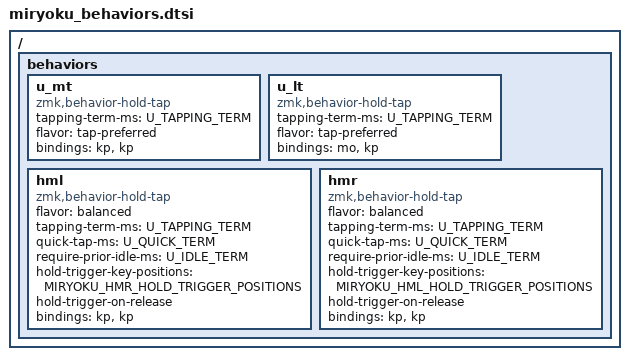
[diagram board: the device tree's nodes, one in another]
// Copyright 2022 Manna Harbour
// https://github.com/manna-harbour/miryoku
/ {
  behaviors {
    u_mt: u_mt {
      compatible = "zmk,behavior-hold-tap";
      #binding-cells = <2>;
      tapping-term-ms = <U_TAPPING_TERM>;
      flavor = "tap-preferred";
      bindings = <&kp>, <&kp>;
    };
    u_lt: u_lt {
      compatible = "zmk,behavior-hold-tap";
      #binding-cells = <2>;
      tapping-term-ms = <U_TAPPING_TERM>;
      flavor = "tap-preferred";
      bindings = <&mo>, <&kp>;
    };
    hml: hml {
      compatible = "zmk,behavior-hold-tap";
      #binding-cells = <2>;
      flavor = "balanced";
      tapping-term-ms = <U_TAPPING_TERM>;
      quick-tap-ms = <U_QUICK_TERM>;
      require-prior-idle-ms = <U_IDLE_TERM>;
      hold-trigger-key-positions = <MIRYOKU_HMR_HOLD_TRIGGER_POSITIONS>;
      hold-trigger-on-release;
      bindings = <&kp>, <&kp>;
    };
    hmr: hmr {
      compatible = "zmk,behavior-hold-tap";
      #binding-cells = <2>;
      flavor = "balanced";
      tapping-term-ms = <U_TAPPING_TERM>;
      quick-tap-ms = <U_QUICK_TERM>;
      require-prior-idle-ms = <U_IDLE_TERM>;
      hold-trigger-key-positions = <MIRYOKU_HML_HOLD_TRIGGER_POSITIONS>;
      hold-trigger-on-release;
      bindings = <&kp>, <&kp>;
    };
  };
};
